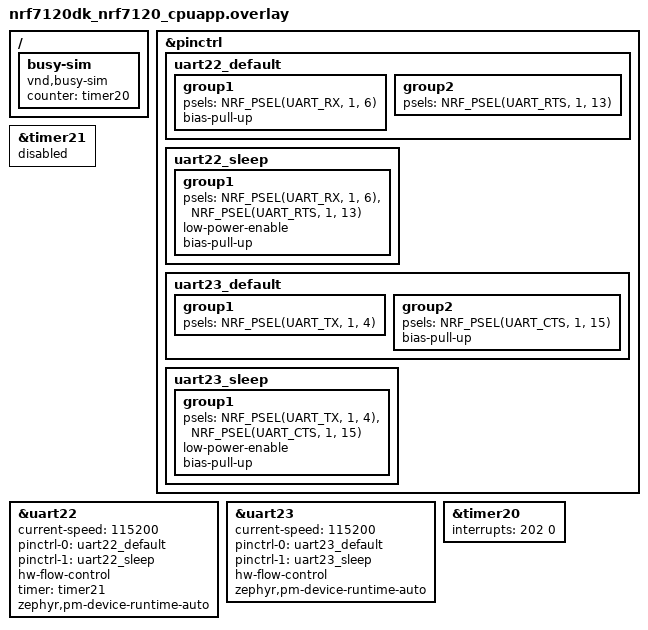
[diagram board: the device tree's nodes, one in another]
/*
 * Copyright (c) 2026 Nordic Semiconductor ASA
 *
 * SPDX-License-Identifier: LicenseRef-Nordic-5-Clause
 */

/* Test requires loopbacks:
 * TX-RX: P1.04 - P1.06
 * CTS-RTS: P1.15 - P1.13
 */

&pinctrl {
	uart22_default: uart22_default {
		group1 {
			psels = <NRF_PSEL(UART_RX, 1, 6)>;
			bias-pull-up;
		};

		group2 {
			psels = <NRF_PSEL(UART_RTS, 1, 13)>;
		};
	};

	uart22_sleep: uart22_sleep {
		group1 {
			psels = <NRF_PSEL(UART_RX, 1, 6)>,
				<NRF_PSEL(UART_RTS, 1, 13)>;
			low-power-enable;
			bias-pull-up;
		};
	};

	uart23_default: uart23_default {
		group1 {
			psels = <NRF_PSEL(UART_TX, 1, 4)>;
		};

		group2 {
			psels = <NRF_PSEL(UART_CTS, 1, 15)>;
			bias-pull-up;
		};
	};

	uart23_sleep: uart23_sleep {
		group1 {
			psels = <NRF_PSEL(UART_TX, 1, 4)>,
				<NRF_PSEL(UART_CTS, 1, 15)>;
			low-power-enable;
			bias-pull-up;
		};
	};
};

&timer21 {
	status = "reserved";
};

dut: &uart22 {
	status = "okay";
	current-speed = <115200>;
	pinctrl-0 = <&uart22_default>;
	pinctrl-1 = <&uart22_sleep>;
	pinctrl-names = "default", "sleep";
	hw-flow-control;
	timer = <&timer21>;
	zephyr,pm-device-runtime-auto;
};

dut_aux: &uart23 {
	status = "okay";
	current-speed = <115200>;
	pinctrl-0 = <&uart23_default>;
	pinctrl-1 = <&uart23_sleep>;
	pinctrl-names = "default", "sleep";
	hw-flow-control;
	zephyr,pm-device-runtime-auto;
};

&timer20 {
	status = "okay";
	interrupts = <202 0>;
};

/ {
	busy-sim {
		compatible = "vnd,busy-sim";
		status = "okay";
		counter = <&timer20>;
	};
};
